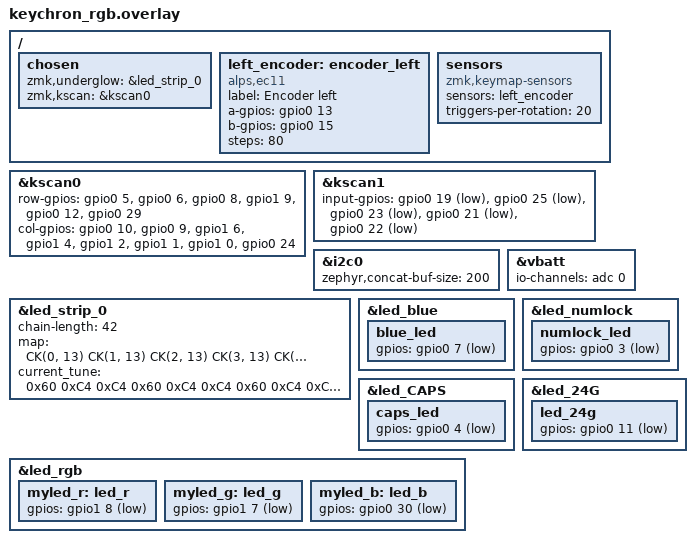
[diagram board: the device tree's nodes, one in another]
/*
 * Copyright (c) 2020 The ZMK Contributors
 *
 * SPDX-License-Identifier: MIT
 */

/ {
    chosen {
             zmk,underglow = &led_strip_0;
             zmk,kscan = &kscan0;
             //zephyr,console =&cdc_acm_uart;
    };
    left_encoder: encoder_left {
        compatible = "alps,ec11";
        status = "okay";
        label = "Encoder left";
        a-gpios = <&gpio0 13 (GPIO_ACTIVE_HIGH )>;
        b-gpios = <&gpio0 15 (GPIO_ACTIVE_HIGH )>;
        steps = <80>;
    };
    sensors: sensors {
        compatible = "zmk,keymap-sensors";
        sensors = <&left_encoder>;
        triggers-per-rotation = <20>;
    };
};

&kscan0 {

     row-gpios
            = <&gpio0 5 (GPIO_ACTIVE_HIGH | GPIO_PULL_DOWN)>    //r0
            , <&gpio0 6 (GPIO_ACTIVE_HIGH | GPIO_PULL_DOWN)>    //r1
            , <&gpio0 8 (GPIO_ACTIVE_HIGH | GPIO_PULL_DOWN)>    //r2
            , <&gpio1 9 (GPIO_ACTIVE_HIGH | GPIO_PULL_DOWN)>    //r3
            , <&gpio0 12 (GPIO_ACTIVE_HIGH | GPIO_PULL_DOWN)>    //r4
            , <&gpio0 29 (GPIO_ACTIVE_HIGH | GPIO_PULL_DOWN)>    //r5
            ;
        col-gpios
            = <&gpio0 10 (GPIO_ACTIVE_HIGH )>   //c0
            , <&gpio0 9 (GPIO_ACTIVE_HIGH)>   //c1
            , <&gpio1 6 (GPIO_ACTIVE_HIGH)>  //c2
            , <&gpio1 4 (GPIO_ACTIVE_HIGH)>  //c3    
            , <&gpio1 2 (GPIO_ACTIVE_HIGH)>   //c4
            , <&gpio1 1  (GPIO_ACTIVE_HIGH)>  //c5
            , <&gpio1 0  (GPIO_ACTIVE_HIGH)>  //c6
            , <&gpio0 24  (GPIO_ACTIVE_HIGH)>  //c7
            ;
};
&kscan1 {

        input-gpios
        = <&gpio0 19 GPIO_ACTIVE_LOW> //mac/win
        , <&gpio0 25  (GPIO_ACTIVE_LOW|GPIO_PULL_UP)> //bt
        , <&gpio0 23  (GPIO_ACTIVE_LOW|GPIO_PULL_UP)> //24g
        , <&gpio0 21 GPIO_ACTIVE_LOW> //charging
        , <&gpio0 22 GPIO_ACTIVE_LOW> //charge done
        ;
};
//&default_transform {
//        columns = <8>;
//        rows = <6>;
//        map =<
//            RC(0,0) RC(0,1) RC(0,2) RC(0,3) RC(0,4) RC(0,5) RC(0,6) RC(0,7)
//            RC(1,0) RC(1,1) RC(1,2) RC(1,3) RC(1,4) RC(1,5) RC(1,6) RC(1,7)
//            RC(2,0) RC(2,1) RC(2,2) RC(2,3) RC(2,4) RC(2,5) RC(2,6)
//            RC(3,0) RC(3,1) RC(3,2) RC(3,3) RC(3,4) RC(3,5) RC(3,6)
//            RC(4,0) RC(4,1) RC(4,2) RC(4,3) RC(4,4) RC(4,5) RC(4,6)
//            RC(5,0) RC(5,1) RC(5,2) RC(5,3) RC(5,4) RC(5,5)
//        >;
        
//};

&i2c0 {
    status = "okay";
    zephyr,concat-buf-size = <200>;   
};

&led_strip_0 {
            chain-length = <42>;
            map = <
            /*   R        G        B */
            //row0
            CK(0, 13) CK(1, 13) CK(2, 13)
            CK(3, 13) CK(4, 13) CK(5, 13)
            CK(6, 13) CK(7, 13) CK(8, 13)
            CK(9, 13) CK(10,13) CK(11,13)
            CK(0,  7) CK(1,  7) CK(2,  7)
            CK(3,  7) CK(4,  7) CK(5,  7)
            CK(6,  7) CK(7,  7) CK(8,  7)

            //row1
            CK(0,  1) CK(1,  1) CK(2,  1)
            CK(0, 12) CK(1, 12) CK(2, 12)
            CK(3, 12) CK(4, 12) CK(5, 12)
            CK(6, 12) CK(7, 12) CK(8, 12)
            CK(9, 12) CK(10,12) CK(11,12)
            CK(0,  6) CK(1,  6) CK(2,  6)
            CK(3,  6) CK(4,  6) CK(5,  6)
            CK(6,  6) CK(7,  6) CK(8,  6)

            //row2
            CK(3,  1) CK(4,  1) CK(5,  1)
            CK(0, 11) CK(1, 11) CK(2, 11)
            CK(3, 11) CK(4, 11) CK(5, 11)
            CK(6, 11) CK(7, 11) CK(8, 11)
            CK(9, 11) CK(10,11) CK(11,11)
            CK(0,  5) CK(1,  5) CK(2,  5)
            CK(3,  5) CK(4,  5) CK(5,  5)

            //row3
            CK(6,  1) CK(7,  1) CK(8,  1)
            CK(0, 10) CK(1, 10) CK(2, 10)
            CK(3, 10) CK(4, 10) CK(5, 10)
            CK(6, 10) CK(7, 10) CK(8, 10)
            CK(9, 10) CK(10,10) CK(11,10)
            CK(0,  4) CK(1,  4) CK(2,  4)
            CK(3,  4) CK(4,  4) CK(5,  4)

            //row4
            CK(9,  1) CK(10, 1) CK(11, 1)
            CK(0,  9) CK(1,  9) CK(2,  9)
            CK(3,  9) CK(4,  9) CK(5,  9)
            CK(6,  9) CK(7,  9) CK(8,  9)
            CK(9,  9) CK(10, 9) CK(11, 9)
            CK(0,  3) CK(1,  3) CK(2,  3)
            CK(3,  3) CK(4,  3) CK(5,  3)

            //row5
            CK(0,  0) CK(1,  0) CK(2,  0)
            CK(0,  8) CK(1,  8) CK(2,  8)
            CK(3,  8) CK(4,  8) CK(5,  8)
            CK(6,  8) CK(7,  8) CK(8,  8)
            CK(9,  8) CK(10, 8) CK(11, 8)
            CK(0,  2) CK(1,  2) CK(2,  2)     
        
            >;

            current_tune =
            <0x60 0xC4 0xC4 0x60 0xC4 0xC4 0x60 0xC4 0xC4 0x60 0xC4 0xC4>;
};
//&usbd {
//    cdc_acm_uart: cdc_acm_uart {
//       compatible = "zephyr,cdc-acm-uart";
//        label = "CDC_ACM_0";
//    };
//};
&vbatt {
    io-channels = <&adc 0>;
};

&led_blue {
  blue_led {
            gpios = <&gpio0 7 GPIO_ACTIVE_LOW>;
           
        };
};

&led_numlock {
        numlock_led {
                gpios = <&gpio0 3 GPIO_ACTIVE_LOW>;

        };
       
};

&led_CAPS {
         caps_led {
                gpios = <&gpio0 4 GPIO_ACTIVE_LOW>;

        };
};

&led_24G {
        led_24g {
                gpios = <&gpio0 11 GPIO_ACTIVE_LOW>;

        };
};

&led_rgb {


        myled_r: led_r {
                gpios = <&gpio1 8 GPIO_ACTIVE_LOW>;

        };
        myled_g: led_g {
                gpios = <&gpio1 7 GPIO_ACTIVE_LOW>;

        };
        myled_b: led_b {
                gpios = <&gpio0 30 GPIO_ACTIVE_LOW>;

        };
};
